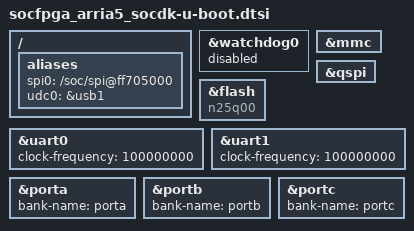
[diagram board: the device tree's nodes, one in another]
// SPDX-License-Identifier: GPL-2.0+
/*
 * U-Boot additions
 *
 * Copyright (C) 2013 Altera Corporation <www.altera.com>
 * Copyright (c) 2018 Simon Goldschmidt
 */

#include "socfpga-common-u-boot.dtsi"

/{
	aliases {
		spi0 = "/soc/spi@ff705000";
		udc0 = &usb1;
	};
};

&watchdog0 {
	status = "disabled";
};

&mmc {
	bootph-all;
};

&qspi {
	bootph-all;
};

&flash {
	compatible = "n25q00", "jedec,spi-nor";
	bootph-all;
};

&uart0 {
	clock-frequency = <100000000>;
	bootph-all;
};

&uart1 {
	clock-frequency = <100000000>;
};

&porta {
	bank-name = "porta";
};

&portb {
	bank-name = "portb";
};

&portc {
	bank-name = "portc";
};
